# gptimer1_secure register map
Vendor: Texas Instruments
Peripheral module from a debugger description file (folder CC35X1E).
Registers are 32-bit, read-write, reset 0x0 unless marked. A register's access mark holds for its fields unless they carry their own. Offsets are as the file gives them; lines under a group give offsets from that group; [hi:lo] are bit positions; {n}, {i} and the like mark numbered series; 'fields as' and 'values as' point back to an identical list; <NAME> marks a mode.

## gptimer1_secure
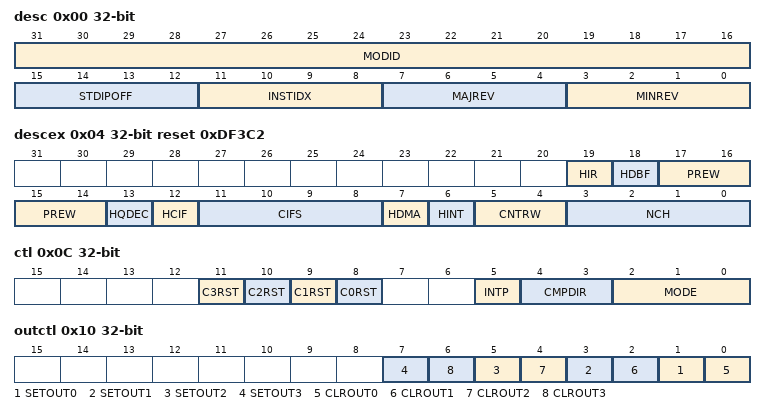
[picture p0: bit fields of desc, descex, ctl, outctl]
0x00 desc ro reset not defined — Description Register. This register provides IP module ID, revision information, instance index and standard MMR registers offset.
  [31:16] MODID — Module identifier used to uniquely identify this IP.
  [15:12] STDIPOFF — Standard IP MMR block offset. Standard IP MMRs are the set of from aggregated IRQ registers till DTB. 0: Standard IP MMRs do not exist 0x1-0xF: Standard IP MMRs begin at offset of (64*[STDIPOFF] from the base IP address)
  [11:8] INSTIDX — IP Instance ID number. If multiple instances of IP exist in the device, this field can identify the instance number.
  [7:4] MAJREV — Major revision of IP.
  [3:0] MINREV — Minor revision of IP.
0x04 descex ro reset 0xDF3C2 — Description Extended This register describes the parameters of the LGPT.
  [19] HIR — Has IR logic.
  [18] HDBF — Has Dead-Band, Fault, and Park logic.
  [17:14] PREW — Prescaler width. The prescaler can maximum be configured to 2^[PREW]-1.
  [13] HQDEC — Has Quadrature Decoder.
  [12] HCIF — Has channel input filter.
  [11:8] CIFS — Channel input filter size. The prevailing state filter can maximum be configured to 2^[CIFS]-1.
  [7] HDMA — Has uDMA output and logic.
  [6] HINT — Has interrupt output and logic.
  [5:4] CNTRW — Counter bit-width. The maximum counter value is equal to 2^[CNTRW]-1.
    0=CNTR16 (16-bit counter.); 1=CNTR24 (24-bit counter.); 2=CNTR32 (32-bit counter.)
  [3:0] NCH — Number of channels.
0x08 startcfg access per field — Start Configuration This register is only for when [CTL.MODE] is configured to one of the SYNC modes. This register defines when this LGPT starts.
  [1:0] LGPT0 rw — LGPT start
    0=EV_SYNC (LGPT starts when synchronized event input is high. Configured here [EVTSVT:LGPTSYNCSEL].)
0x0C ctl access per field — Timer Control
  [11] C3RST wo — Channel 3 reset.
    0=NOEFF (No effect.); 1=RST (Reset [C3CC.*], [PC3CC.*], and [C3CFG.*].)
  [10] C2RST wo — Channel 2 reset.
    0=NOEFF (No effect.); 1=RST (Reset [C2CC.*], [PC2CC.*], and [C2CFG.*].)
  [9] C1RST wo — Channel 1 reset.
    0=NOEFF (No effect.); 1=RST (Reset [C1CC.*], [PC1CC.*], and [C1CFG.*].)
  [8] C0RST wo — Channel 0 reset.
    0=NOEFF (No effect.); 1=RST (Reset [C0CC], [PC0CC], and [C0CFG].)
  [5] INTP rw — Interrupt Phase. This bit field controls when the [RIS.TGT] and [RIS.ZERO] interrupts are set.
    0=EARLY ([RIS.TGT] and [RIS.ZERO] are set one system clock cycle after [CNTR.*] = TARGET/ZERO.); 1=LATE ([RIS.TGT] and [RIS.ZERO] are set one timer clock cycle after [CNTR.*] = TARGET/ZERO.)
  [4:3] CMPDIR rw — Compare direction. This bit field controls the direction the counter must have in order to set the [RIS.*] compare interrupts.
    0=BOTH (Compare [RIS.*] fields are set on up count and down count.); 1=UP (Compare [RIS.*] fields are only set on up count.); 2=DOWN (Compare [RIS.*] fields are only set on down count.)
  [2:0] MODE rw — Timer mode control The [CNTR.*] restarts from 0 when MODE is written to UP_ONCE, UP_PER, UPDWN_PER, QDEC, SYNC_UP_ONCE, SYNC_UP_PER or SYNC_UPDWN_PER. When writing MODE all internally queued updates to the channels and [TGT.*] is cleared. When configuring the timer, MODE should be the last thing to configure. If changing timer configuration after MODE has been set is necessary, instructions, if any, given in the configuration registers should be followed. See for example [C0CFG.*].
    0=DIS (Disable timer. Updates to counter, channels, and events stop.); 1=UP_ONCE (Count up once. The timer increments from 0 to target value, then stops and sets MODE to DIS.); 2=UP_PER (Count up periodically. The timer increments from 0 to target value, repeatedly. Period = (target value + 1) * timer clock period); 3=UPDWN_PER (Count up and down periodically. The timer counts from 0 to target value and back to 0, repeatedly. Period = (target value * 2) * timer clock period); 4=QDEC (The timer functions as a quadrature decoder. IOC input 0, IOC input 1 and IOC input 2 are used respectively as PHA, PHB and IDX inputs. IDX can be turned off by setting [C2CFG.EDGE] = NONE. The timer clock frequency sets the sample rate of the QDEC logic. This frequency can be configured in [PRECFG.*].); 5=SYNC_UP_ONCE (Start counting up once synchronous to another LGPT, selected within [STARTCFG.*]. The timer is started by setting [CTL.MODE] = UP_ONCE automatically. It then functions as a normal timer in [CTL.MODE] = UP_ONCE, incrementing from 0 to target value, then stops and sets MODE to DIS.); 6=SYNC_UP_PER (Start counting up periodically synchronous to another LGPT, selected within [STARTCFG.*]. The timer is started by setting [CTL.MODE] = UP_PER automatically. It then operates as a normal timer in [CTL.MODE] = UP_PER, incrementing from 0 to target value, repeatedly. Period = (target value * 2) * timer clock period); 7=SYNC_UPDWN_PER (Start counting up and down periodically synchronous to another LGPT, selected within [STARTCFG.*]. The timer is started by setting [CTL.MODE] = UPDWN_PER automatically. It then operates as a normal timer in [CTL.MODE] = UPDWN_PER, counting from 0 to target value and back to 0, repeatedly. Period = (target value * 2) * timer clock period)
0x10 outctl access per field — Output Control Set and clear individual outputs manually. Manual update of an output takes priority over automatic channel updates to the same output. It is not possible to set and clear an output at the same time, such requests will be neglected. An output can be automatically cleared, set, toggled, or pulsed by each channel, listed in decreasing order of priority. The action with highest priority happens when multiple channels want to update an output at the same time. All outputs are connected to the event fabric and the IO controller. The outputs going to the IO controller have an additional complementary output, this output is the inverted IO output. Both the IO and the IO complementary outputs are passed through an IO Controller, see [IOCTL.*].
  [2n+1] SETOUT{n} wo (n=0..3) — Set output {n}. Write 1 to set output {n}.
  [2n] CLROUT{n} wo (n=0..3) — Clear output {n}. Write 1 to clear output {n}.
0x14 cntr — Counter The counter of this timer. After [CTL.MODE] is set the counter updates at the rate specified in [PRECFG.*].
  [15:0] VAL — Current counter value. If [CTL.MODE] = QDEC this can be used to set the initial counter value during QDEC.
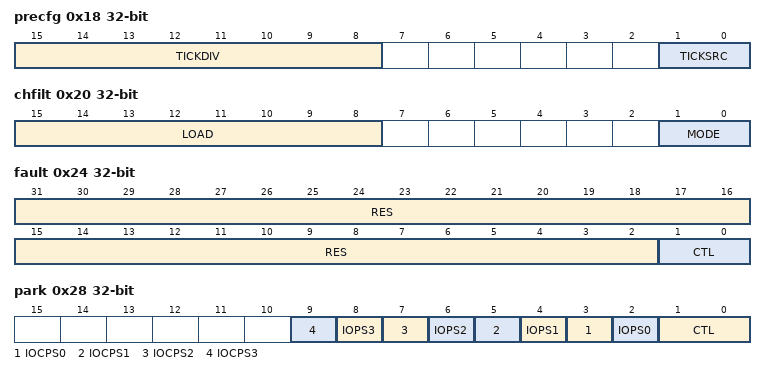
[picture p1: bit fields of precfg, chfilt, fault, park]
0x18 precfg access per field — Clock Prescaler Configuration This register is used to set the timer clock period. The prescaler is a counter which counts down from the value [TICKDIV]. When the prescaler counter reaches zero, [CNTR.*] is updated. The field [TICKDIV] effectively divides the prescaler tick source. The timer clock frequency can be calculated as [TICKSRC]/([TICKDIV]+1).
  [15:8] TICKDIV rw — Tick division. [TICKDIV] determines the timer clock frequency for the counter, and timer output updates. The timer clock frequency is the clock selected by [TICKSRC] divided by ([TICKDIV] + 1). This inverse is the timer clock period. 0x00: Divide by 1. 0x01: Divide by 2. ... 0xFF: Divide by 256.
  [1:0] TICKSRC rw — Prescaler tick source. [TICKSRC] determines the source which decrements the prescaler.
    0=CLK (Prescaler is updated at the system clock.); 1=RISE_TICK (Prescaler is updated at the rising edge of TICKEN.); 2=FALL_TICK (Prescaler is updated at the falling edge of TICKEN.); 3=BOTH_TICK (Prescaler is updated at both edges of TICKEN.)
0x1C preevent access per field — Prescaler Event This register is used to output a logic high signal before the zero crossing of the prescaler counter. The output is routed to the IOC.
  [7:0] VAL rw — Sets the HIGH time of the prescaler event output. Event goes high when the prescaler counter equals [VAL]. Event goes low when prescaler counter is 0. Note: - Can be used to precharge or turn an external component on for a short time before sampling, like in QDEC. - If there is a requirement to create such events that have very short periods compared to timer clock period, use two timers. One timer acts as prescaler and event generator for another timer.
0x20 chfilt access per field — Channel Input Filter This register is used to configure the filter on the channel inputs. The configuration is for all inputs. The filter is enabled when a channel is in capture mode. The input to the filter is passed to the edge detection logic if [LOAD] + 1 consecutive input samples are equal. The filter functions as a down counter, counting down every input sample. If two consecutive samples are unequal, the filter counter restarts from [LOAD]. If the filter counter reaches zero, the input signal is valid and passed to the edge detection logic. The channel filter should only be configured while the [CTL.MODE] = DIS. Configuring the filter while the timer is running can result in unexpected behavior.
  [15:8] LOAD rw — The input of the channel filter is passed to the edge detection logic after [LOAD] + 1 consecutive equal samples.
  [1:0] MODE rw — Channel filter mode
    0=BYPASS (Filter is bypassed. No Filter is used.); 1=CLK (Filter is clocked by system clock.); 2=TICKSRC (Filter is clocked by [PRECFG.TICKSRC].); 3=TIMERCLK (Filter is clocked by timer clock.)
0x24 fault access per field — Fault This register is used to configure the fault input logic. Primary use scenario is to select [CTL] before starting the timer. Follow these steps to configure [CTL] while [CTL.MODE] is different from DIS: - Set [C0CFG.EDGE] to NONE. - Configure [CTL]. - Wait for three system clock periods before setting [C0CFG.EDGE] different from NONE. These steps prevent fault detection caused by expired signal values in synchronize and edge-detection circuit.
  [31:2] RES ro — Software should not rely on the value of a reserved. Writing any other value than the reset value may result in undefined behavior.
  [1:0] CTL rw — Fault control On active fault input the counter can optionally stop. If the counter stops this is done by hardware, software must then restart the timer if wanted. The fault input overrides channel 0 IOC input when [CTL] != DIS. This means that channel 0 receives fault as input signal when [C0CFG.INPUT] = IO and [CTL] != DIS. [CHFILT.*] can be used to avoid glitching on the fault input. Fault is level triggered, the polarity is set by the [C0CFG.EDGE] field. Here [C0CFG.EDGE] = RISE gives active high and [C0CFG.EDGE] = FALL gives active low polarity. Fault is typically used together with [PARK.*] to stop the PWM signal to an external motor control circuit safely. Configure [PARK.*] to ensure predefined values of the PWM outputs. If [CTL] != DIS the [RIS.FAULT] interrupt is set immediately when the fault input is active while [CTL.MODE] != DIS. The three modes of fault is described below: [CTL] = IMMEDIATE In this mode the counter stops immediately on an active fault input. This is done by hardware by setting [CTL.MODE] = DIS. To start the counter software must set [CTL.MODE] != DIS. When the counter has stopped, the input synchronizers and the channel filter is not running. This means that if [RIS.FAULT] is cleared it will not be set again while [CTL.MODE] = DIS. [CTL] = ZEROCOND In this mode the counter stops when [CNTR.*] = 0 after an active fault input. If the [RIS.FAULT] interrupt has been cleared by software before [CNTR.*] = 0, and the fault input is inactive, the counter will continue as normal. When the counter stops on zero, it can be started again by clearing the [RIS.FAULT] interrupt if the fault input is inactive. To change the counter mode set [CTL.MODE] = DIS, clear the [RIS.FAULT] interrupt, then start timer in wanted mode. [CTL] = IRQ In this mode only the [RIS.FAULT] flag is set on an active fault input.
    0=DIS (Disable. The timer ignores fault.); 1=IMMEDIATE (Immediate reaction. The counter stops immediately on fault.); 2=ZERCOND (Zero condition. The counter stops when [CNTR.*] = 0.); 3=IRQ (Interrupt request. Only set [RIS.FAULT] on active fault.)
0x28 park access per field — Park This register configures how the outputs should be set in Park mode. Park mode is either entered by debug halt or fault. Park mode is activated when the counter stops. Park mode is inactive when the counter starts. When park mode is active all outputs are set to their predefined states. For IO output signals which have enabled dead band, a dead band insertion will be done before switching to the predefined state.
  [2n+3] IOCPS{n} rw (n=0..3) — IO Complementary Park State {n} Park state for IO Complementary output {n}.
    0=LOW (Output is set low in park mode.); 1=HIGH (Output is set high in park mode.)
  [8] IOPS3 rw — IO Park State 3 Park state for IO output 3.
    values as IOCPS0
  [6] IOPS2 rw — IO Park State 2 Park state for IO output 2.
    values as IOCPS0
  [4] IOPS1 rw — IO Park State 1 Park state for IO output 1.
    values as IOCPS0
  [2] IOPS0 rw — IO Park State 0 Park state for IO output 0.
    1=HIGH (Output is set high in park mode.); 0=LOW (Output is set low in park mode.)
  [1:0] CTL rw — Park Control.
    0=DIS (Disable park mode.); 1=FAULT (Enter park mode on fault.); 2=DEBUG (Enter park mode on debug.); 3=BOTH (Enter parkmode on fault or debug.)
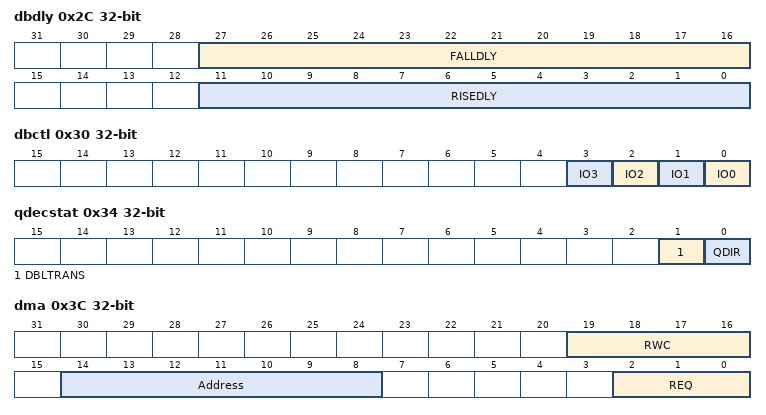
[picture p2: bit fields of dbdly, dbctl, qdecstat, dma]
0x2C dbdly access per field — Dead Band Delay This register is used to insert a dead band delay when generating complementary PWM signals. To enable dead band, on for example IO output 0, create a reference PWM signal on Output 0, then set [DBCTL.IOC0] = EN. TBD: 12-bit width fall delay and rise delay may be excessive, if 8-bits are enough we can join DBDLY and DBCTL.
  [27:16] FALLDLY rw — Fall delay. The number of system clock periods inserted between the fall of the dead band reference signal and the rise of the inverted output signal.
  [11:0] RISEDLY rw — Rise delay. The number of system clock periods inserted between the rise of the dead band reference signal and the rise of the output signal.
0x30 dbctl access per field — Dead Band Control This register is used to enable dead band for IOC outputs.
  [all] fields
    0=DIS (Disable); 1=EN (Enable)
  [n] IO{n} rw (n=0..3) — Enable dead band on IO and IO complementary output {n}.
0x34 qdecstat ro — Quadrature Decoder Status This register can be used during QDEC mode to check the status of the quadrature decoder.
  [1] DBLTRANS — Double transition
    0=NONE (Single or no transition on phase inputs.); 1=DBL (Double transition on phase inputs.)
  [0] QDIR — Direction of count during QDEC mode.
    0=UP (Up (PHA leads PHB)); 1=DOWN (Down (PHB leads PHA))
0x38 irgen access per field — IR Generation Use this register to generate IR codes. When [CTL] = 1, an AND gate is enabled between IO output 0 in LGPT0 and IC output 0 in LGPT1. The output of the gate overrides IO output 0 in LGPT0. See [OUTCTL.*] for explanation of outputs. To generate IR codes let LGPT0 generate the carrier wave on output 0. Set this output as tick input of LGPT1, with [PRECFG.TICKSRC] = FALL_TICK. Generate wanted IR codes by adjusting LGPT1 [PTGT.*] and [PC0CC.*].
  [0] CTL rw — Control
    0=DIS (Disable.); 1=EN (Enable.)
0x3C dma access per field — Direct Memory Access This register is used to enable DMA requests from the timer and set the register addresses which the DMA will access (read/write). Choose DMA request source by setting the [REQ] field. The setting of the corresponding interrupt in the [RIS.*] registers also sets the DMA request. Upon a DMA request defined by [REQ] an internal address pointer is set to [RWADDR]*4. Every access to [DMARW.*] will increment the internal pointer by 4 such that the next DMA access will be to the next register. The internal pointer will stop after [RWCNTR] increments. Further access will be ignored.
  [19:16] RWC rw — The read/write counter. RWCNTR+1 is the number of times the DMA can access (read/write) the [DMARW] register. For each DMA access to [DMARW] an internal counter is incremented, writing to the next address field. [RWADDR] + 4*[RWCNTR] is the final register address which can be accessed by the DMA.
  [14:8] Address rw — The base address which the DMA access when reading/writing [DMARW]. The base address is set by taking the 9 LSB of the physical address and divide by 4. For example, if you wanted the [RWADDR] to point to the [PTGT] register you should set [RWADDR] = 0x0FC/4.
  [2:0] REQ rw — DMA request trigger
    0=DIS (Disabled); 3=FAULT (Setting of [RIS.FAULT] generates a DMA request.); 1=TGT (Setting of [RIS.TGT] generates a DMA request.); 2=ZERO (Setting of [RIS.ZERO] generates a DMA request.); {v}=C{v-4}CC (Setting of [RIS.C{v-4}CC] generates a DMA request.) (v=4..7)
0x40 dmarw — Direct Memory Access This register is used by the DMA to access (read/write) register inside this LGPT module. Each access to this register will increment the internal DMA address counter. See [DMA.*] for description.
  [15:0] VAL — DMA read write value. The value that is read/written from/to the registers.
0x44 adctrg access per field — ADC Trigger This register is used to enable ADC trigger from the timer. Choose ADC trigger source by setting the [SRC] field. The setting of the corresponding interrupt in the [RIS.*] registers also sets the ADC trigger.
  [2:0] SRC rw — ADC request trigger
    0=DIS (Disabled); 3=FAULT (Setting of [RIS.FAULT] generates an ADC trigger.); 1=TGT (Setting of [RIS.TGT] generates an ADC trigger.); 2=ZERO (Setting of [RIS.ZERO] generates an ADC trigger.); {v}=C{v-4}CC (Setting of [RIS.C{v-4}CC] generates an ADC trigger.) (v=4..7)
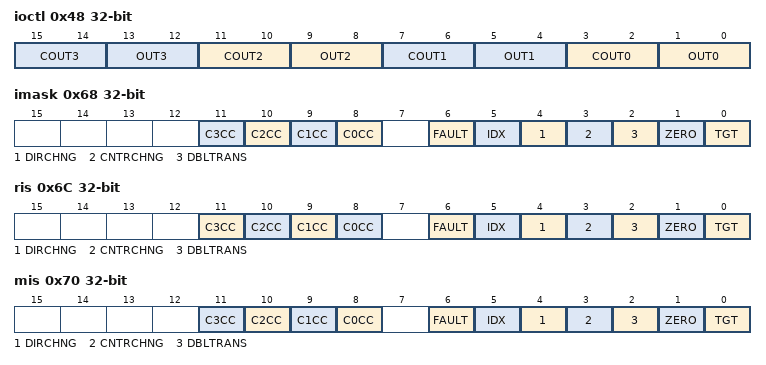
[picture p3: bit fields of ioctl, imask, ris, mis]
0x48 ioctl access per field — IO Controller This register controls the IO outputs.
  [4n+3:4n+2] COUT{n} rw (n=0..3) — IO complementary output {n} control This bit field controls IO complementary output {n}.
    0=NRM (Normal output. The IO complementary output is not changed.); 1=LOW (Driven low. The IO complementary output is driven low.); 2=HIGH (Driven high. The IO complementary output is driven high.); 3=INV (Inverted value. The IO complementary output is inverted.)
  [4n+1:4n] OUT{n} rw (n=0..3) — IO output {n} control This bit field controls IO output {n}.
    0=NRM (Normal output. The IO output is not changed.); 1=LOW (Driven low. The IO output is driven low.); 2=HIGH (Driven high. The IO output is driven high.); 3=INV (Inverted value. The IO output is inverted.)
0x68 imask access per field — Interrupt mask. This register selects interrupt sources which are allowed to pass from [RIS.*] to [MIS.*] when the corresponding bit-fields are set to 1.
  [all] fields
    0=DIS (Disable); 1=EN (Enable)
  [n+8] C{n}CC rw (n=0..3) — Enable [RIS.C{n}CC] interrupt.
  [6] FAULT rw — Enable [RIS.FAULT] interrupt.
  [5] IDX rw — Enable [RIS.IDX] interrupt.
  [4] DIRCHNG rw — Enable [RIS.DIRCHNG] interrupt.
  [3] CNTRCHNG rw — Enable [RIS.CNTRCHNG] interrupt.
  [2] DBLTRANS rw — Enable [RIS.DBLTRANS] interrupt.
  [1] ZERO rw — Enable [RIS.ZERO] interrupt.
  [0] TGT rw — Enable [RIS.TGT] interrupt.
0x6C ris ro — Raw interrupt status. This register reflects the state of all pending interrupts, regardless of masking. This register allows the user to implement a poll scheme. A flag set in this register can be cleared by writing 1 to the corresponding [ICLR.*] register bit.
  [11] C3CC — Status of the [C3CC] interrupt. The interrupt is set when [C3CC] has capture or compare event.
    0=DIS (Disable); 1=EN (Enable)
  [10] C2CC — Status of the [C2CC] interrupt. The interrupt is set when [C2CC] has capture or compare event.
    0=CLR (Cleared); 1=SET
  [9] C1CC — Status of the [C1CC] interrupt. The interrupt is set when [C1CC] has capture or compare event.
    0=CLR (Cleared); 1=SET
  [8] C0CC — Status of the [C0CC] interrupt. The interrupt is set when [C0CC] has capture or compare event.
    0=CLR (Cleared); 1=SET
  [6] FAULT — Status of the [FAULT] interrupt. The interrupt is set immediately on active fault input.
    0=CLR (Cleared); 1=SET
  [5] IDX — Status of the [IDX] interrupt. The interrupt is set when [IDX] is active.
    0=CLR (Cleared); 1=SET
  [4] DIRCHNG — Status of the [DIRCHNG] interrupt. The interrupt is set when the direction of the counter changes.
    0=CLR (Cleared); 1=SET
  [3] CNTRCHNG — Status of the [CNTRCHNG] interrupt. The interrupt is set when the counter increments or decrements.
    0=CLR (Cleared); 1=SET
  [2] DBLTRANS — Status of the [DBLTRANS] interrupt. The interrupt is set when a double transition has happened during QDEC mode.
    0=CLR (Cleared); 1=SET
  [1] ZERO — Status of the [ZERO] interrupt. The interrupt is set when [CNTR.*] = 0.
    0=CLR (Cleared); 1=SET
  [0] TGT — Status of the [TGT] interrupt. The interrupt is set when [CNTR.*] = [TGT.*].
    0=CLR (Cleared); 1=SET
0x70 mis ro — Masked interrupt status. This register is simply a bit-wise AND of the contents of [IMASK.*] and RIS.*] registers. A flag set in this register can be cleared by writing 1 to the corresponding [ICLR.*] register bit.
  [all] fields
    0=CLR (Cleared); 1=SET
  [n+8] C{n}CC (n=0..3) — Masked status of the [RIS.C{n}CC] interrupt.
  [6] FAULT — Masked status of the [RIS.FAULT] interrupt.
  [5] IDX — Masked status of the [RIS.IDX] interrupt.
  [4] DIRCHNG — Masked status of the [RIS.DIRCHNG] interrupt.
  [3] CNTRCHNG — Masked status of the [RIS.CNTRCHNG] interrupt.
  [2] DBLTRANS — Masked status of the [RIS.DBLTRANS] interrupt.
  [1] ZERO — Masked status of the [RIS.ZERO] interrupt.
  [0] TGT — Masked status of the [RIS.TGT] interrupt.
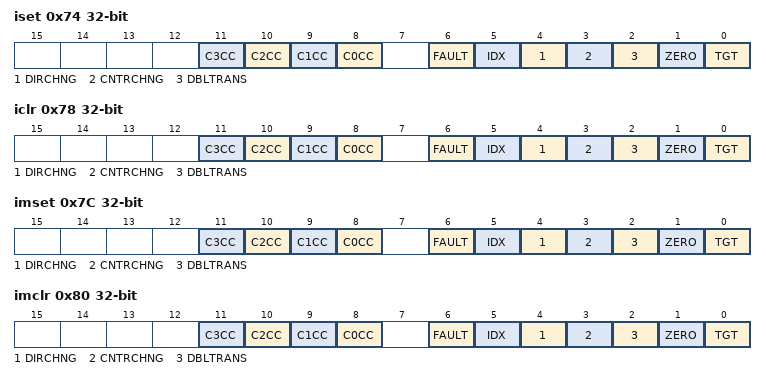
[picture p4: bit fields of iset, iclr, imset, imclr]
0x74 iset wo — Interrupt set register. This register can used by software for diagnostics and safety checking purposes. Writing a 1 to a bit in this register will set the event and the corresponding [RIS.*] bit also gets set. If the corresponding [IMASK.*] bit is set, then the corresponding [MIS.*] register bit also gets set.
  [all] fields
    0=NO_EFFECT; 1=SET
  [n+8] C{n}CC (n=0..3) — Set the [RIS.C{n}CC] interrupt.
  [6] FAULT — Set the [RIS.FAULT] interrupt.
  [5] IDX — Set the [RIS.IDX] interrupt.
  [4] DIRCHNG — Set the [RIS.DIRCHNG] interrupt.
  [3] CNTRCHNG — Set the [RIS.CNTRCHNG] interrupt.
  [2] DBLTRANS — Set the [RIS.DBLTRANS] interrupt.
  [1] ZERO — Set the [RIS.ZERO] interrupt.
  [0] TGT — Set the [RIS.TGT] interrupt.
0x78 iclr wo — Interrupt clear register. This register allows software to clear interrupts. Writing a 1 to a bit in this register will clear the event and the corresponding [RIS.*] bit also gets cleared. If the corresponding [IMASK.*] bit is set, then the corresponding [MIS.*] register bit also gets cleared.
  [all] fields
    0=NO_EFFECT; 1=CLR (Clear)
  [n+8] C{n}CC (n=0..3) — Clear the [RIS.C{n}CC] interrupt.
  [6] FAULT — Clear the [RIS.FAULT] interrupt.
  [5] IDX — Clear the [RIS.IDX] interrupt.
  [4] DIRCHNG — Clear the [RIS.DIRCHNG] interrupt.
  [3] CNTRCHNG — Clear the [RIS.CNTRCHNG] interrupt.
  [2] DBLTRANS — Clear the [RIS.DBLTRANS] interrupt.
  [1] ZERO — Clear the [RIS.ZERO] interrupt.
  [0] TGT — Clear the [RIS.TGT] interrupt.
0x7C imset wo — Interrupt mask set register. Writing a 1 to a bit in this register will set the corresponding [IMASK.*] bit.
  [all] fields
    0=NO_EFFECT; 1=SET
  [n+8] C{n}CC (n=0..3) — Set the [MIS.C{n}CC] mask.
  [6] FAULT — Set the [MIS.FAULT] mask.
  [5] IDX — Set the [MIS.IDX] mask.
  [4] DIRCHNG — Set the [MIS.DIRCHNG] mask.
  [3] CNTRCHNG — Set the [MIS.CNTRCHNG] mask.
  [2] DBLTRANS — Set the [MIS.DBLTRANS] mask.
  [1] ZERO — Set the [MIS.ZERO] mask.
  [0] TGT — Set the [MIS.TGT] mask.
0x80 imclr wo — Interrupt mask clear register. Writing a 1 to a bit in this register will clear the corresponding [IMASK.*] bit.
  [all] fields
    0=NO_EFFECT; 1=CLR (Clear)
  [n+8] C{n}CC (n=0..3) — Clear the [MIS.C{n}CC] mask.
  [6] FAULT — Clear the [MIS.FAULT] mask.
  [5] IDX — Clear the [MIS.IDX] mask.
  [4] DIRCHNG — Clear the [MIS.DIRCHNG] mask.
  [3] CNTRCHNG — Clear the [MIS.CNTRCHNG] mask.
  [2] DBLTRANS — Clear the [MIS.DBLTRANS] mask.
  [1] ZERO — Clear the [MIS.ZERO] mask.
  [0] TGT — Clear the [MIS.TGT] mask.
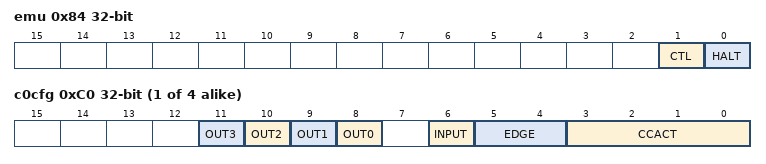
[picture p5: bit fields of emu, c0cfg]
0x84 emu access per field — Debug control This register can be used to freeze the timer when CPU halts when [HALT] is set to 1. When [HALT] is set to 0, or when the CPU releases debug halt, the filters and edge detection logic is flushed and the timer starts. For setting a predefined output value during a CPU debug halt, [PARK.*], if the timer has this register, should be configured additionally. If this timer does not have the [PARK.*] register a predefined output value during CPU halt is not possible.
  [1] CTL rw — Halt control. Configure when the counter shall stop upon CPU halt. This bitfield only applies if [HALT] = 1.
    0=IMMEDIATE (Immediate reaction. The counter stops immediately on debug halt.); 1=ZERCOND (Zero condition. The counter stops when [CNTR.*] = 0.)
  [0] HALT rw — Halt LGPT when CPU is halted in debug.
    0=DIS (Disable.); 1=EN (Enable.)
{0xC0+4i} c{i}cfg access per field (i=0..3) — Channel {i} Configuration This register configures channel function and enables outputs. Each channel has an edge-detection circuit. The the edge-detection circuit is: - enabled while [CCACT] selects a capture function and [CTL.MODE] is different from DIS. - flushed while [CCACT] selects a capture function and [CTL.MODE] is changed from DIS to another mode. The flush action uses two system clock periods. It prevents capture events caused by expired signal values stored in the edge-detection circuit. The channel input signal enters the edge-detection circuit. False capture events can occur when: - the edge-detection circuit contains expired signal samples and the circuit is enabled without flush as described above. - the [CCACT] field is reconfigured while CTL.MODE is different from DIS. Primary use scenario is to select [CCACT] before starting the timer. Follow these steps to configure [CCACT] to a capture action while [CTL.MODE] is different from DIS: - Set [EDGE] to NONE. - Configure [CCACT]. - Wait for three system clock periods before setting [EDGE] different from NONE. These steps prevent capture events caused by expired signal values in edge-detection circuit.
  [n+8] OUT{n} rw (n=0..3) — Output {n} enable. When 0 < [CCACT] < 8, OUT{n} becomes zero after a capture or compare event.
    0=DIS (Channel {i} does not control output {n}.); 1=EN (Channel {i} controls output {n}.)
  [6] INPUT rw — Select channel input.
    0=EV (Event fabric); 1=IO (IO controller)
  [5:4] EDGE rw — Determines the edge that triggers the channel input event. This happens post filter.
    0=NONE (Input is turned off.); 1=RISE (Input event is triggered at rising edge.); 2=FALL (Input event is triggered at falling edge.); 3=BOTH (Input event is triggered at both edges.)
  [3:0] CCACT rw — Capture-Compare action. Capture-Compare action defines 15 different channel functions that utilize capture, compare, and zero events. In every compare event the timer looks at the current value of [CNTR.*]. The corresponding output event will be set 1 timer period after [CNTR.*] = [C{i}CC.*].
    0=DIS (Disable channel.); 1=SET_ON_CAPT_DIS (Set on capture, and then disable channel. Channel function sequence: - Set enabled outputs on capture event and copy [CNTR.VAL] to [C{i}CC.VAL]. - Disable channel. Primary use scenario is to select this function before starting the timer. Follow these steps to select this function while [CTL.MODE] is different from DIS: - Set CCACT to SET_ON_CAPT with no output enable. - Configure [INPUT] (optional). - Wait for three timer clock periods as defined in [PRECFG.*] before setting CCACT to SET_ON_CAPT_DIS. Output enable is optional. These steps prevent capture events caused by expired signal values in edge-detection circuit.); 10=CLR_ON_0_TGL_ON_CMP (Clear on zero, toggle on compare repeatedly. Channel function sequence: - Clear enabled outputs when [CNTR.VAL] = 0. - Toggle enabled outputs when [C{i}CC.VAL] = [CNTR.VAL]. Set [CTL.MODE] to UPDWN_PER for center-aligned PWM generation. Duty cycle is given by: When [C{i}CC.VAL] <= [TGT.VAL]: Duty cycle = 1 - ( [C{i}CC.VAL] / [TGT.VAL] ). When [C{i}CC.VAL] > [TGT.VAL]: Duty cycle = 0. Enabled outputs are set when [C{i}CC.VAL] = 0 and [CNTR.VAL] = 0.); 11=SET_ON_0_TGL_ON_CMP (Set on zero, toggle on compare repeatedly. Channel function sequence: - Set enabled outputs when [CNTR.VAL] = 0. - Toggle enabled outputs when [C{i}CC.VAL] = [CNTR.VAL]. Set [CTL.MODE] to UP_PER for edge-aligned PWM generation. Duty cycle is given by: When [C{i}CC.VAL] <= [TGT.VAL]: Duty cycle = [C{i}CC.VAL] / ( [TGT.VAL] + 1 ). When [C{i}CC.VAL] > [TGT.VAL]: Duty cycle = 1. Enabled outputs are cleared when [C{i}CC.VAL] = 0 and [CNTR.VAL] = 0.); 12=CLR_ON_CMP (Clear on compare repeatedly. Channel function sequence: - Clear enabled outputs when [C{i}CC.VAL] = [CNTR.VAL].); 13=SET_ON_CMP (Set on compare repeatedly. Channel function sequence: - Set enabled outputs when [C{i}CC.VAL] = [CNTR.VAL].); 14=TGL_ON_CMP (Toggle on compare repeatedly. Channel function sequence: - Toggle enabled outputs when [C{i}CC.VAL] = [CNTR.VAL].); 15=PULSE_ON_CMP (Pulse on compare repeatedly. Channel function sequence: - Pulse enabled outputs when [C{i}CC.VAL] = [CNTR.VAL]. The output is high for two timer clock periods.); 2=CLR_ON_0_TGL_ON_CMP_DIS (Clear on zero, toggle on compare, and then disable channel. Channel function sequence: - Clear enabled outputs when [CNTR.VAL] = 0. - Toggle enabled outputs when [C{i}CC.VAL] = [CNTR.VAL]. - Disable channel. Enabled outputs are set when [C{i}CC.VAL] = 0 and [CNTR.VAL] = 0.); 3=SET_ON_0_TGL_ON_CMP_DIS (Set on zero, toggle on compare, and then disable channel. Channel function sequence: - Set enabled outputs when [CNTR.VAL] = 0. - Toggle enabled outputs when [C{i}CC.VAL] = [CNTR.VAL]. - Disable channel. Enabled outputs are cleared when [C{i}CC.VAL] = 0 and [CNTR.VAL] = 0.); 4=CLR_ON_CMP_DIS (Clear on compare, and then disable channel. Channel function sequence: - Clear enabled outputs when [C{i}CC.VAL] = [CNTR.VAL]. - Disable channel.); 5=SET_ON_CMP_DIS (Set on compare, and then disable channel. Channel function sequence: - Set enabled outputs when [C{i}CC.VAL] = [CNTR.VAL]. - Disable channel.); 6=TGL_ON_CMP_DIS (Toggle on compare, and then disable channel. Channel function sequence: - Toggle enabled outputs when [C{i}CC.VAL] = [CNTR.VAL]. - Disable channel.); 7=PULSE_ON_CMP_DIS (Pulse on compare, and then disable channel. Channel function sequence: - Pulse enabled outputs when [C{i}CC.VAL] = [CNTR.VAL]. - Disable channel. The output is high for two timer clock periods.); 8=PER_PULSE_WIDTH_MEAS (Period and pulse width measurement. Continuously capture period and pulse width of the signal selected by [INPUT] relative to the signal edge given by [EDGE]. Set enabled outputs and [RIS.C{i}CC] when [C{i}CC.VAL] contains signal period and [PC{i}CC.VAL] contains signal pulse width. Notes: - Make sure to configure [INPUT] and CCACT when [CTL.MODE] equals DIS, then set [CTL.MODE] to UP_ONCE or UP_PER. - The counter restarts in the selected timer mode when [C{i}CC.VAL] contains the signal period. - If more than one channel uses this function, the channels will perform this function one at a time. The channel with lowest number has priority and performs the function first. Next measurement starts when current measurement completes successfully or times out. A timeout occurs when counter equals target. - To observe a timeout event the [RIS.TGT] interrupt can be used, or another channel can be configured to SET_ON_CMP with compare value equal [TGT]. Signal property requirements: - Signal Period >= 2 * ( 1 + [PRECFG.TICKDIV] ) * timer clock period. - Signal Period <= MAX([CNTR.*]) * (1 + [PRECFG.TICKDIV] ) * timer clock period. - Signal low and high phase >= (1 + [PRECFG.TICKDIV] ) * timer clock period.); 9=SET_ON_CAPT (Set on capture repeatedly. Channel function sequence: - Set enabled outputs on capture event and copy [CNTR.VAL] to [C{i}CC.VAL].)
0xFC ptgt — Pipeline Target A read or write to this register will clear the [RIS.ZERO] and [RIS.TGT] interrupt. If [CTL.MODE] != QDEC. Target value for next counter period. The timer will copy [PTGT.VAL] to [TGT.VAL] on the upcoming [CNTR.*] zero crossing only if [PTGT.VAL] has been written. The copy does not happen when restarting the timer. This is useful to avoid period jitter in PWM applications with time-varying period, sometimes referenced as phase corrected PWM. If [CTL.MODE] = QDEC The [CNTR.*] value is updated with VALUE on IDX if the counter is counting down. If the counter is counting up, [CNTR.*] is loaded with zero on IDX. In this mode the VALUE is not loaded into [TGT] on zero crossing.
  [15:0] VAL — The pipleline target value.
{0x100+4i} pc{i}cc (i=0..3) — Pipeline Channel {i} Capture Compare
  [15:0] VAL — Pipeline Capture Compare value. User defined pipeline compare value or channel-updated capture value. A read or write to this register will clear the [RIS.C{i}CC] interrupt. Compare mode: An update of VAL will be transferred to [C{i}CC.VAL] when the next [CNTR.VAL] is zero and [CTL.MODE] is different from DIS. This is useful for PWM generation and prevents jitter on the edges of the generated signal. Capture mode: When [C{i}CFG.CCACT] equals PER_PULSE_WIDTH_MEAS then VAL contains the width of the low or high phase of the selected signal. This is specified by [C{i}CFG.EDGE].
0x13C tgt — Target User defined counter target. A read or write to this register will clear the [RIS.ZERO] and [RIS.TGT] interrupt.
  [15:0] VAL — User defined counter target value.
{0x140+4i} c{i}cc (i=0..3) — Channel {i} Capture Compare
  [15:0] VAL — Capture Compare value. User defined compare value or channel-updated capture value. A read or write to this register will clear the [RIS.C{i}CC] interrupt. Compare mode: VAL is compared against [CNTR.VAL] and an event is generated as specified by [C{i}CFG.CCACT] when these are equal. Capture mode: The current counter value is stored in VAL when a capture event occurs. [C{i}CFG.CCACT] determines if VAL is a signal period or a regular capture value.
0x17C ptgtnc — Pipeline Target No Clear Use this register to read or write to [PTGT.*] without clearing the [RIS.ZERO] and [RIS.TGT] interrupt.
  [15:0] VAL — A read or write to this register will not clear the [RIS.TGT] interrupt. If [CTL.MODE] != QDEC. Target value for next counter period. The timer copies VAL to [TGT.VAL] when [CNTR.VAL] becomes 0. The copy does not happen when restarting the timer. This is useful to avoid period jitter in **PWM** applications with time-varying period, sometimes referenced as phase corrected PWM. If [CTL.MODE] = QDEC. The [CNTR.VAL] is updated with VAL on IDX. VAL is not loaded into [TGT.VAL] when [CNTR.VAL] becomes 0.
{0x180+4i} pc{i}ccnc (i=0..3) — Pipeline Channel {i} Capture Compare No Clear
  [15:0] VAL — Pipeline Capture Compare value. User defined pipeline compare value or channel-updated capture value. A read or write to this register will not clear the [RIS.C{i}CC] interrupt. Compare mode: An update of VAL will be transferred to [C{i}CC.VAL] when the next [CNTR.VAL] is zero and [CTL.MODE] is different from DIS. This is useful for **PWM** generation and prevents jitter on the edges of the generated signal. Capture mode: When [C{i}CFG.CCACT] equals PER_PULSE_WIDTH_MEAS then VAL contains the width of the low or high phase of the selected signal. This is specified by [C{i}CFG.EDGE].
0x1BC tgtnc — Target No Clear Use this register to read or write to [TGT.*] without clearing the [RIS.ZERO] and [RIS.TGT] interrupt.
  [15:0] VAL — User defined counter target value.
{0x1C0+4i} c{i}ccnc (i=0..3) — Channel {i} Capture Compare No Clear
  [15:0] VAL — Capture Compare value. User defined compare value or channel-updated capture value. A read or write to this register will not clear the [RIS.C{i}CC] interrupt. Compare mode: VAL is compared against [CNTR.VAL] and an event is generated as specified by [C{i}CFG.CCACT] when these are equal. Capture mode: The current counter value is stored in VAL when a capture event occurs. [C{i}CFG.CCACT] determines if VAL is a signal period or a regular capture value.
0x1000 clk_en_reg access per field — Clock Enable Register
  [0] ENABLE rw — GPTimer main clock Enable
